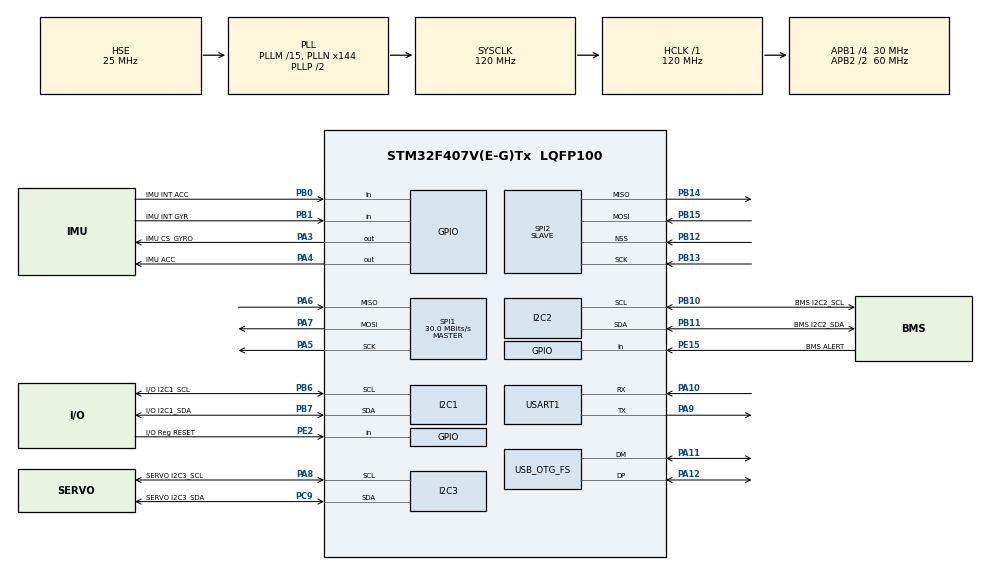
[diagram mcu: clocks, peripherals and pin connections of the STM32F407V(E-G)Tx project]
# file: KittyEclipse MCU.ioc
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Mcu.Family=STM32F4
Mcu.Name=STM32F407V(E-G)Tx
Mcu.Package=LQFP100
NVIC.PriorityGroup=NVIC_PRIORITYGROUP_4
PA10.Mode=Asynchronous
PA10.Signal=USART1_RX
PA11.Mode=Device_Only
PA11.Signal=USB_OTG_FS_DM
PA12.Mode=Device_Only
PA12.Signal=USB_OTG_FS_DP
PA13.Mode=Serial_Wire
PA13.Signal=SYS_JTMS-SWDIO
PA14.Mode=Serial_Wire
PA14.Signal=SYS_JTCK-SWCLK
PA3.GPIO_Label=IMU CS_GYRO
PA3.Signal=GPIO_Output
PA4.GPIO_Label=IMU ACC
PA4.Signal=GPIO_Output
PA5.Mode=Full_Duplex_Master
PA5.Signal=SPI1_SCK
PA6.Mode=Full_Duplex_Master
PA6.Signal=SPI1_MISO
PA7.Mode=Full_Duplex_Master
PA7.Signal=SPI1_MOSI
PA8.GPIO_Label=SERVO I2C3_SCL
PA8.Mode=I2C
PA8.Signal=I2C3_SCL
PA9.Mode=Asynchronous
PA9.Signal=USART1_TX
PB0.GPIO_Label=IMU INT ACC
PB0.Signal=GPIO_Input
PB1.GPIO_Label=IMU INT GYR
PB1.Signal=GPIO_Input
PB10.GPIO_Label=BMS I2C2_SCL
PB10.Mode=I2C
PB10.Signal=I2C2_SCL
PB11.GPIO_Label=BMS I2C2_SDA
PB11.Mode=I2C
PB11.Signal=I2C2_SDA
PB12.Mode=NSS_Signal_Hard_Input
PB12.Signal=SPI2_NSS
PB13.Mode=Full_Duplex_Slave
PB13.Signal=SPI2_SCK
PB14.Mode=Full_Duplex_Slave
PB14.Signal=SPI2_MISO
PB15.Mode=Full_Duplex_Slave
PB15.Signal=SPI2_MOSI
PB6.GPIO_Label=I/O I2C1_SCL
PB6.Mode=I2C
PB6.Signal=I2C1_SCL
PB7.GPIO_Label=I/O I2C1_SDA
PB7.Mode=I2C
PB7.Signal=I2C1_SDA
PC14-OSC32_IN.Mode=LSE-External-Clock-Source
PC14-OSC32_IN.Signal=RCC_OSC32_IN
PC15-OSC32_OUT.Mode=LSE-External-Clock-Source
PC15-OSC32_OUT.Signal=RCC_OSC32_OUT
PC9.GPIO_Label=SERVO I2C3_SDA
PC9.Mode=I2C
PC9.Signal=I2C3_SDA
PE15.GPIO_Label=BMS ALERT
PE15.Signal=GPIO_Input
PE2.GPIO_Label=I/O Reg RESET
PE2.Signal=GPIO_Input
PH0-OSC_IN.Mode=HSE-External-Oscillator
PH0-OSC_IN.Signal=RCC_OSC_IN
PH1-OSC_OUT.Mode=HSE-External-Oscillator
PH1-OSC_OUT.Signal=RCC_OSC_OUT
ProjectManager.HeapSize=0x200
ProjectManager.StackSize=0x400
ProjectManager.TargetToolchain=STM32CubeIDE
RCC.48MHZClocksFreq_Value=48000000
RCC.AHBFreq_Value=120000000
RCC.APB1CLKDivider=RCC_HCLK_DIV4
RCC.APB1Freq_Value=30000000
RCC.APB1TimFreq_Value=60000000
RCC.APB2CLKDivider=RCC_HCLK_DIV2
RCC.APB2Freq_Value=60000000
RCC.APB2TimFreq_Value=120000000
RCC.CortexFreq_Value=120000000
RCC.HCLKFreq_Value=120000000
RCC.HSE_VALUE=25000000
RCC.HSI_VALUE=16000000
RCC.PLLM=15
RCC.PLLN=144
RCC.PLLQ=5
RCC.SYSCLKFreq_VALUE=120000000
RCC.SYSCLKSource=RCC_SYSCLKSOURCE_PLLCLK
RCC.VCOOutputFreq_Value=240000000
SPI1.BaudRatePrescaler=SPI_BAUDRATEPRESCALER_2
SPI1.CalculateBaudRate=30.0 MBits/s
SPI1.Direction=SPI_DIRECTION_2LINES
SPI1.Mode=SPI_MODE_MASTER
SPI1.VirtualType=VM_MASTER
SPI2.Direction=SPI_DIRECTION_2LINES
SPI2.Mode=SPI_MODE_SLAVE
SPI2.VirtualNSS=VM_NSSHARD
SPI2.VirtualType=VM_SLAVE
USART1.VirtualMode=VM_ASYNC
USB_OTG_FS.VirtualMode=Device_Only
VP_RTC_VS_RTC_Activate.Mode=RTC_Enabled
board=custom

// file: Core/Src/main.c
/* USER CODE BEGIN Header */
/**
  ******************************************************************************
  * @file           : main.c
  * @brief          : Main program body
  ******************************************************************************
  * @attention
  *
  * Copyright (c) 2025 STMicroelectronics.
  * All rights reserved.
  *
  * This software is licensed under terms that can be found in the LICENSE file
  * in the root directory of this software component.
  * If no LICENSE file comes with this software, it is provided AS-IS.
  *
  ******************************************************************************
  */
/* USER CODE END Header */
#include "main.h"
#include "uart_jetson.h"

I2C_HandleTypeDef hi2c1;
I2C_HandleTypeDef hi2c2;
I2C_HandleTypeDef hi2c3;

RTC_HandleTypeDef hrtc;

SPI_HandleTypeDef hspi1;
SPI_HandleTypeDef hspi2;

UART_HandleTypeDef huart1;

PCD_HandleTypeDef hpcd_USB_OTG_FS;

/* USER CODE BEGIN PV */
uint8_t tx_data[] = "Hello Jetson!\r\n";
uint8_t rx_data[32];
/* USER CODE END PV */

void SystemClock_Config(void);
static void MX_GPIO_Init(void);
static void MX_I2C1_Init(void);
static void MX_USART1_UART_Init(void);
static void MX_USB_OTG_FS_PCD_Init(void);
static void MX_I2C2_Init(void);
static void MX_I2C3_Init(void);
static void MX_SPI1_Init(void);
static void MX_SPI2_Init(void);
static void MX_RTC_Init(void);

int main(void)
{

  /* MCU Configuration--------------------------------------------------------*/

  /* Reset of all peripherals, Initializes the Flash interface and the Systick. */
  HAL_Init();

  /* Configure the system clock */
  SystemClock_Config();

  /* Initialize all configured peripherals */
  MX_GPIO_Init();
  MX_I2C1_Init();
  MX_USART1_UART_Init();
  MX_USB_OTG_FS_PCD_Init();
  MX_I2C2_Init();
  MX_I2C3_Init();
  MX_SPI1_Init();
  MX_SPI2_Init();
  MX_RTC_Init();
  /* USER CODE BEGIN 2 */
  UART_Jetson_SendData(&huart1, tx_data, sizeof(tx_data) - 1);
  /* USER CODE END 2 */

  /* Infinite loop */
  while (1)
  {
	    UART_Jetson_ReceiveData(&huart1, rx_data, 1);  // Read 1 byte
	    UART_Jetson_SendData(&huart1, rx_data, 1);     // Echo back
	    HAL_Delay(10);
  }
}

void SystemClock_Config(void)
{
  RCC_OscInitTypeDef RCC_OscInitStruct = {0};
  RCC_ClkInitTypeDef RCC_ClkInitStruct = {0};

  /** Configure the main internal regulator output voltage
  */
  __HAL_RCC_PWR_CLK_ENABLE();
  __HAL_PWR_VOLTAGESCALING_CONFIG(PWR_REGULATOR_VOLTAGE_SCALE1);

  /** Initializes the RCC Oscillators according to the specified parameters
  * in the RCC_OscInitTypeDef structure.
  */
  RCC_OscInitStruct.OscillatorType = RCC_OSCILLATORTYPE_LSI|RCC_OSCILLATORTYPE_HSE;
  RCC_OscInitStruct.HSEState = RCC_HSE_ON;
  RCC_OscInitStruct.LSIState = RCC_LSI_ON;
  RCC_OscInitStruct.PLL.PLLState = RCC_PLL_ON;
  RCC_OscInitStruct.PLL.PLLSource = RCC_PLLSOURCE_HSE;
  RCC_OscInitStruct.PLL.PLLM = 15;
  RCC_OscInitStruct.PLL.PLLN = 144;
  RCC_OscInitStruct.PLL.PLLP = RCC_PLLP_DIV2;
  RCC_OscInitStruct.PLL.PLLQ = 5;
  if (HAL_RCC_OscConfig(&RCC_OscInitStruct) != HAL_OK)
  {
    Error_Handler();
  }

  /** Initializes the CPU, AHB and APB buses clocks
  */
  RCC_ClkInitStruct.ClockType = RCC_CLOCKTYPE_HCLK|RCC_CLOCKTYPE_SYSCLK
                              |RCC_CLOCKTYPE_PCLK1|RCC_CLOCKTYPE_PCLK2;
  RCC_ClkInitStruct.SYSCLKSource = RCC_SYSCLKSOURCE_PLLCLK;
  RCC_ClkInitStruct.AHBCLKDivider = RCC_SYSCLK_DIV1;
  RCC_ClkInitStruct.APB1CLKDivider = RCC_HCLK_DIV4;
  RCC_ClkInitStruct.APB2CLKDivider = RCC_HCLK_DIV2;

  if (HAL_RCC_ClockConfig(&RCC_ClkInitStruct, FLASH_LATENCY_3) != HAL_OK)
  {
    Error_Handler();
  }
}

static void MX_I2C1_Init(void)
{

  hi2c1.Instance = I2C1;
  hi2c1.Init.ClockSpeed = 100000;
  hi2c1.Init.DutyCycle = I2C_DUTYCYCLE_2;
  hi2c1.Init.OwnAddress1 = 0;
  hi2c1.Init.AddressingMode = I2C_ADDRESSINGMODE_7BIT;
  hi2c1.Init.DualAddressMode = I2C_DUALADDRESS_DISABLE;
  hi2c1.Init.OwnAddress2 = 0;
  hi2c1.Init.GeneralCallMode = I2C_GENERALCALL_DISABLE;
  hi2c1.Init.NoStretchMode = I2C_NOSTRETCH_DISABLE;
  if (HAL_I2C_Init(&hi2c1) != HAL_OK)
  {
    Error_Handler();
  }

}

static void MX_I2C2_Init(void)
{

  hi2c2.Instance = I2C2;
  hi2c2.Init.ClockSpeed = 100000;
  hi2c2.Init.DutyCycle = I2C_DUTYCYCLE_2;
  hi2c2.Init.OwnAddress1 = 0;
  hi2c2.Init.AddressingMode = I2C_ADDRESSINGMODE_7BIT;
  hi2c2.Init.DualAddressMode = I2C_DUALADDRESS_DISABLE;
  hi2c2.Init.OwnAddress2 = 0;
  hi2c2.Init.GeneralCallMode = I2C_GENERALCALL_DISABLE;
  hi2c2.Init.NoStretchMode = I2C_NOSTRETCH_DISABLE;
  if (HAL_I2C_Init(&hi2c2) != HAL_OK)
  {
    Error_Handler();
  }

}

static void MX_I2C3_Init(void)
{

  hi2c3.Instance = I2C3;
  hi2c3.Init.ClockSpeed = 100000;
  hi2c3.Init.DutyCycle = I2C_DUTYCYCLE_2;
  hi2c3.Init.OwnAddress1 = 0;
  hi2c3.Init.AddressingMode = I2C_ADDRESSINGMODE_7BIT;
  hi2c3.Init.DualAddressMode = I2C_DUALADDRESS_DISABLE;
  hi2c3.Init.OwnAddress2 = 0;
  hi2c3.Init.GeneralCallMode = I2C_GENERALCALL_DISABLE;
  hi2c3.Init.NoStretchMode = I2C_NOSTRETCH_DISABLE;
  if (HAL_I2C_Init(&hi2c3) != HAL_OK)
  {
    Error_Handler();
  }

}

static void MX_RTC_Init(void)
{

  /** Initialize RTC Only
  */
  hrtc.Instance = RTC;
  hrtc.Init.HourFormat = RTC_HOURFORMAT_24;
  hrtc.Init.AsynchPrediv = 127;
  hrtc.Init.SynchPrediv = 255;
  hrtc.Init.OutPut = RTC_OUTPUT_DISABLE;
  hrtc.Init.OutPutPolarity = RTC_OUTPUT_POLARITY_HIGH;
  hrtc.Init.OutPutType = RTC_OUTPUT_TYPE_OPENDRAIN;
  if (HAL_RTC_Init(&hrtc) != HAL_OK)
  {
    Error_Handler();
  }

}

static void MX_SPI1_Init(void)
{

  /* SPI1 parameter configuration*/
  hspi1.Instance = SPI1;
  hspi1.Init.Mode = SPI_MODE_MASTER;
  hspi1.Init.Direction = SPI_DIRECTION_2LINES;
  hspi1.Init.DataSize = SPI_DATASIZE_8BIT;
  hspi1.Init.CLKPolarity = SPI_POLARITY_LOW;
  hspi1.Init.CLKPhase = SPI_PHASE_1EDGE;
  hspi1.Init.NSS = SPI_NSS_SOFT;
  hspi1.Init.BaudRatePrescaler = SPI_BAUDRATEPRESCALER_2;
  hspi1.Init.FirstBit = SPI_FIRSTBIT_MSB;
  hspi1.Init.TIMode = SPI_TIMODE_DISABLE;
  hspi1.Init.CRCCalculation = SPI_CRCCALCULATION_DISABLE;
  hspi1.Init.CRCPolynomial = 10;
  if (HAL_SPI_Init(&hspi1) != HAL_OK)
  {
    Error_Handler();
  }

}

static void MX_SPI2_Init(void)
{

  /* SPI2 parameter configuration*/
  hspi2.Instance = SPI2;
  hspi2.Init.Mode = SPI_MODE_SLAVE;
  hspi2.Init.Direction = SPI_DIRECTION_2LINES;
  hspi2.Init.DataSize = SPI_DATASIZE_8BIT;
  hspi2.Init.CLKPolarity = SPI_POLARITY_LOW;
  hspi2.Init.CLKPhase = SPI_PHASE_1EDGE;
  hspi2.Init.NSS = SPI_NSS_HARD_INPUT;
  hspi2.Init.FirstBit = SPI_FIRSTBIT_MSB;
  hspi2.Init.TIMode = SPI_TIMODE_DISABLE;
  hspi2.Init.CRCCalculation = SPI_CRCCALCULATION_DISABLE;
  hspi2.Init.CRCPolynomial = 10;
  if (HAL_SPI_Init(&hspi2) != HAL_OK)
  {
    Error_Handler();
  }

}

static void MX_USART1_UART_Init(void)
{

  huart1.Instance = USART1;
  huart1.Init.BaudRate = 115200;
  huart1.Init.WordLength = UART_WORDLENGTH_8B;
  huart1.Init.StopBits = UART_STOPBITS_1;
  huart1.Init.Parity = UART_PARITY_NONE;
  huart1.Init.Mode = UART_MODE_TX_RX;
  huart1.Init.HwFlowCtl = UART_HWCONTROL_NONE;
  huart1.Init.OverSampling = UART_OVERSAMPLING_16;
  if (HAL_UART_Init(&huart1) != HAL_OK)
  {
    Error_Handler();
  }

}

static void MX_USB_OTG_FS_PCD_Init(void)
{

  hpcd_USB_OTG_FS.Instance = USB_OTG_FS;
  hpcd_USB_OTG_FS.Init.dev_endpoints = 4;
  hpcd_USB_OTG_FS.Init.speed = PCD_SPEED_FULL;
  hpcd_USB_OTG_FS.Init.dma_enable = DISABLE;
  hpcd_USB_OTG_FS.Init.phy_itface = PCD_PHY_EMBEDDED;
  hpcd_USB_OTG_FS.Init.Sof_enable = DISABLE;
  hpcd_USB_OTG_FS.Init.low_power_enable = DISABLE;
  hpcd_USB_OTG_FS.Init.lpm_enable = DISABLE;
  hpcd_USB_OTG_FS.Init.vbus_sensing_enable = DISABLE;
  hpcd_USB_OTG_FS.Init.use_dedicated_ep1 = DISABLE;
  if (HAL_PCD_Init(&hpcd_USB_OTG_FS) != HAL_OK)
  {
    Error_Handler();
  }

}

static void MX_GPIO_Init(void)
{
  GPIO_InitTypeDef GPIO_InitStruct = {0};

  /* GPIO Ports Clock Enable */
  __HAL_RCC_GPIOE_CLK_ENABLE();
  __HAL_RCC_GPIOC_CLK_ENABLE();
  __HAL_RCC_GPIOH_CLK_ENABLE();
  __HAL_RCC_GPIOA_CLK_ENABLE();
  __HAL_RCC_GPIOB_CLK_ENABLE();

  /*Configure GPIO pin Output Level */
  HAL_GPIO_WritePin(GPIOA, IMU_CS_GYRO_Pin|IMU_ACC_Pin, GPIO_PIN_RESET);

  /*Configure GPIO pins : I_O_Reg_RESET_Pin BMS_ALERT_Pin */
  GPIO_InitStruct.Pin = I_O_Reg_RESET_Pin|BMS_ALERT_Pin;
  GPIO_InitStruct.Mode = GPIO_MODE_INPUT;
  GPIO_InitStruct.Pull = GPIO_NOPULL;
  HAL_GPIO_Init(GPIOE, &GPIO_InitStruct);

  /*Configure GPIO pins : IMU_CS_GYRO_Pin IMU_ACC_Pin */
  GPIO_InitStruct.Pin = IMU_CS_GYRO_Pin|IMU_ACC_Pin;
  GPIO_InitStruct.Mode = GPIO_MODE_OUTPUT_PP;
  GPIO_InitStruct.Pull = GPIO_NOPULL;
  GPIO_InitStruct.Speed = GPIO_SPEED_FREQ_LOW;
  HAL_GPIO_Init(GPIOA, &GPIO_InitStruct);

  /*Configure GPIO pins : IMU_INT_ACC_Pin IMU_INT_GYR_Pin */
  GPIO_InitStruct.Pin = IMU_INT_ACC_Pin|IMU_INT_GYR_Pin;
  GPIO_InitStruct.Mode = GPIO_MODE_INPUT;
  GPIO_InitStruct.Pull = GPIO_NOPULL;
  HAL_GPIO_Init(GPIOB, &GPIO_InitStruct);

}

void Error_Handler(void)
{
  __disable_irq();
  while (1)
  {
  }
}
